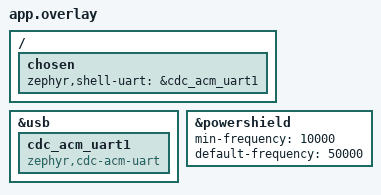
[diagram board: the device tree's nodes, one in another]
/*
 * The board's default chosen (zephyr,console and thingset,can) are already
 * set in spin.dts. Here we only add a second USB-CDC-ACM UART instance and
 * route the ThingSet shell to it, so it doesn't collide with the console.
 */

/ {
	chosen {
		zephyr,shell-uart = &cdc_acm_uart1;
	};
};

&usb {
	cdc_acm_uart1: cdc_acm_uart1 {
		compatible = "zephyr,cdc-acm-uart";
	};
};

/*
 * Test bench (opposition method): the 2026-11-27 campaign sweeps 10-100 kHz.
 * The Twist sets min-frequency = 50 kHz, which makes the HRTIM refuse lower
 * frequencies; 10 kHz selects a coarser prescaler (~2.9 ns tick), still far
 * finer than the 1-degree steps of the old protocol.
 */
&powershield {
	min-frequency = <10000>;
	default-frequency = <50000>;
};
